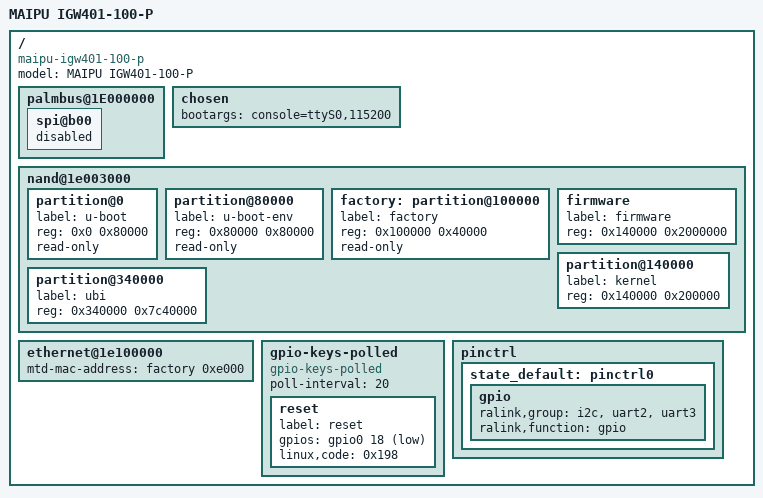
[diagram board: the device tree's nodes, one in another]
/dts-v1/;

/include/ "mt7621.dtsi"

/ {
	compatible = "maipu-igw401-100-p", "mediatek,mt7621-soc";
	model = "MAIPU IGW401-100-P";

	palmbus@1E000000 {
		spi@b00 {
			status="disabled";
		};
	};

	chosen {
		bootargs = "console=ttyS0,115200";
	};

	nand@1e003000 {
		status = "okay";

		partition@0 {
			label = "u-boot";
			reg = <0x0 0x80000>;
			read-only;
		};

		partition@80000 {
			label = "u-boot-env";
			reg = <0x80000 0x80000>;
			read-only;
		};

		factory: partition@100000 {
			label = "factory";
			reg = <0x100000 0x40000>;
			read-only;
		};
		
		firmware {
			label = "firmware";
			reg = <0x140000 0x2000000>;
		};

		partition@140000 {
			label = "kernel";
			reg = <0x140000 0x200000>;
		};

		partition@340000 {
			label = "ubi";
			reg = <0x340000 0x7c40000>;
		};
	};

	ethernet@1e100000 {
		mtd-mac-address = <&factory 0xe000>;
	};	

	gpio-keys-polled {
		compatible = "gpio-keys-polled";
		#address-cells = <1>;
		#size-cells = <0>;
		poll-interval = <20>;

		reset {
			label = "reset";
			gpios = <&gpio0 18 1>;
			linux,code = <0x198>;
		};
	};

	pinctrl {
		state_default: pinctrl0 {
			gpio {
				ralink,group = "i2c", "uart2", "uart3";
				ralink,function = "gpio";
			};
		};
	};
};
